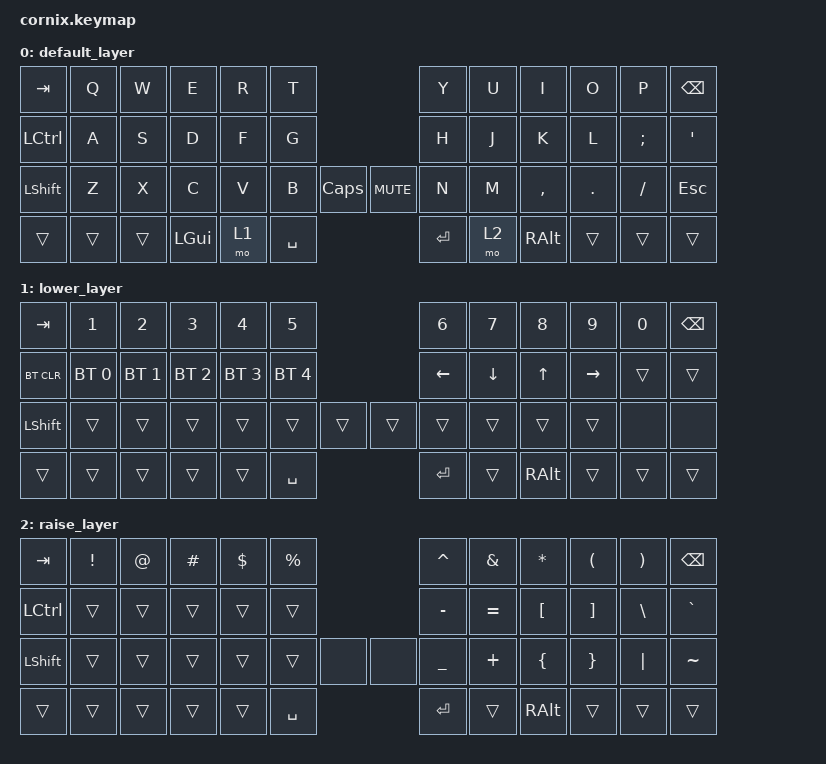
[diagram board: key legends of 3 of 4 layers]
#include <behaviors/naginata.dtsi>

/ {

    macros {
        ng_on: ng_on {
            compatible = "zmk,behavior-macro";
            #binding-cells = <0>;
            bindings
                = <&macro_tap &kp LANGUAGE_1 &kp INTERNATIONAL_4 &to 1>
                ;
        };
        ng_off: ng_off {
            compatible = "zmk,behavior-macro";
            #binding-cells = <0>;
            bindings
                = <&macro_tap &kp LANGUAGE_2 &kp INTERNATIONAL_5 &to 0>
                ;
        };
    };

    combos {
        compatible = "zmk,combos";
        combo_ng_on {
            timeout-ms = <300>;
            key-positions = <15 16>; // H, Jのキー位置に書き換えてください
            bindings = <&ng_on>;
            layers = <0>; // デフォルトレイヤーが0の前提
        };
        combo_ng_off {
            timeout-ms = <300>;
            key-positions = <13 14>; // F, Gのキー位置に書き換えてください
            bindings = <&ng_off>;
            layers = <0 3>; // デフォルトレイヤーが0、薙刀式レイヤーが3の前提
        };
    };


    keymap {
        compatible = "zmk,keymap";

        default_layer {
            // -----------------------------------------------------------------------------------------
            // |  TAB |  Q  |  W  |  E  |  R  |  T  |      |   |      |  Y  |  U  |  I  |  O  |  P  | BKSP |
            // | CTRL |  A  |  S  |  D  |  F  |  G  |      |   |      |  H  |  J  |  K  |  L  |  ;  |  '   |
            // | SHFT |  Z  |  X  |  C  |  V  |  B  |      |   |      |  N  |  M  |  ,  |  .  |  /  | ESC  |
            //                    | GUI | LWR | SPC | SPC2 |   | ENT2 | ENT | RSE | ALT |

            bindings = <
&kp TAB    &kp Q   &kp W   &kp E     &kp R  &kp T                                &kp Y    &kp U  &kp I      &kp O    &kp P     &kp BSPC
&kp LCTRL  &kp A   &kp S   &kp D     &kp F  &kp G                                &kp H    &kp J  &kp K      &kp L    &kp SEMI  &kp SQT
&kp LSHFT  &kp Z   &kp X   &kp C     &kp V  &kp B      &kp CAPSLOCK  &kp K_MUTE  &kp N    &kp M  &kp COMMA  &kp DOT  &kp FSLH  &kp ESC
&trans     &trans  &trans  &kp LGUI  &mo 1  &kp SPACE                            &kp RET  &mo 2  &kp RALT   &trans   &trans    &trans
            >;

            sensor-bindings =
                <&inc_dec_kp C_VOLUME_UP C_VOLUME_DOWN>,
                <&inc_dec_kp PAGE_UP PAGE_DOWN>;
        };

        lower_layer {
            // -----------------------------------------------------------------------------------------
            // |  TAB |  1  |  2  |  3  |  4  |  5  |      |   |      |  6  |  7  |  8  |  9  |  0  | BKSP |
            // | BTCLR| BT1 | BT2 | BT3 | BT4 | BT5 |      |   |      | LFT | DWN |  UP | RGT |     |      |
            // | SHFT |     |     |     |     |     |      |   |      |     |     |     |     |     |      |
            //                    | GUI |     | SPC | SPC2 |   | ENT2 | ENT |     | ALT |

            bindings = <
&kp TAB     &kp N1        &kp N2        &kp N3        &kp N4        &kp N5                        &kp N6    &kp N7    &kp N8    &kp N9     &kp N0  &kp BSPC
&bt BT_CLR  &bt BT_SEL 0  &bt BT_SEL 1  &bt BT_SEL 2  &bt BT_SEL 3  &bt BT_SEL 4                  &kp LEFT  &kp DOWN  &kp UP    &kp RIGHT  &trans  &trans
&kp LSHFT   &trans        &trans        &trans        &trans        &trans        &trans  &trans  &trans    &trans    &trans    &trans     &none   &none
&trans      &trans        &trans        &trans        &trans        &kp SPACE                     &kp RET   &trans    &kp RALT  &trans     &trans  &trans
            >;
        };

        raise_layer {
            // -----------------------------------------------------------------------------------------
            // |  TAB |  !  |  @  |  #  |  $  |  %  |      |   |      |  ^  |  &  |  *  |  (  |  )  | BKSP |
            // | CTRL |     |     |     |     |     |      |   |      |  -  |  =  |  [  |  ]  |  \  |  `   |
            // | SHFT |     |     |     |     |     |      |   |      |  _  |  +  |  {  |  }  |  |  |  ~   |
            //                    | GUI |     | SPC | SPC2 |   | ENT2 | ENT |     | ALT |

            bindings = <
&kp TAB    &kp EXCL  &kp AT  &kp HASH  &kp DLLR  &kp PRCNT                &kp CARET  &kp AMPS   &kp ASTERISK  &kp LPAR  &kp RPAR  &kp BSPC
&kp LCTRL  &trans    &trans  &trans    &trans    &trans                   &kp MINUS  &kp EQUAL  &kp LBKT      &kp RBKT  &kp BSLH  &kp GRAVE
&kp LSHFT  &trans    &trans  &trans    &trans    &trans     &none  &none  &kp UNDER  &kp PLUS   &kp LBRC      &kp RBRC  &kp PIPE  &kp TILDE
&trans     &trans    &trans  &trans    &trans    &kp SPACE                &kp RET    &trans     &kp RALT      &trans    &trans    &trans
            >;
        };

        // 薙刀式に必要な31キー(Enterもシフトキーにしたいときは32キー)を定義してください。
        // &kpの代わりに&ngを使います。通常はデフォルトレイヤーの次に配置してください(レイヤー番号1)。
        naginata_layer { 
            bindings = <
            // +----------+----------+----------+----------+----------+----------+----------+----------+----------+----------
                &ng Q      &ng W      &ng E      &ng R      &ng T      &ng Y      &ng U      &ng I      &ng O      &ng P
                &ng A      &ng S      &ng D      &ng F      &ng G      &ng H      &ng J      &ng K      &ng L      &ng SEMI
                &ng Z      &ng X      &ng C      &ng V      &ng B      &ng N      &ng M      &ng COMMA  &ng DOT    &ng SLASH
                                      &kp LSHIFT &mo LOWER  &ng SPACE  &ng ENTER  &mo RAISE  &kp RCTRL
                >;
        };
    };
};
